# RTS591x register map
Vendor: Realtek Semiconductor Corp.; Series: RTS591x Series; File version: 1.0
CPU: ARMV8MML r0p0, little endian, MPU, FPU, VTOR, 3 interrupt priority bits, 4 SAU regions
Registers are 32-bit, read-write, reset 0x0 unless marked. A register's access mark holds for its fields unless they carry their own. Offsets are from the block's base; [hi:lo] are bit positions; {n}, {i} and the like mark numbered series.

## UART — UART Controller
Base 0x40010100
0x00 RBR ro — RECEIVE BUFFER REGISTER
  [7:0] DATA — Receive Buffer
0x00 THR (alternate view of RBR) — TRANSMIT HOLDING REGISTER
  [7:0] DATA — Transmit Holding
0x00 DLL (alternate view of RBR) — DIVISOR LATCH LOW REGISTER
  [7:0] DIVL — Divisor Latch Low Byte
0x04 DLH — DIVISOR LATCH HIGH REGISTER
  [7:0] DIVH — Divisor Latch High Byte
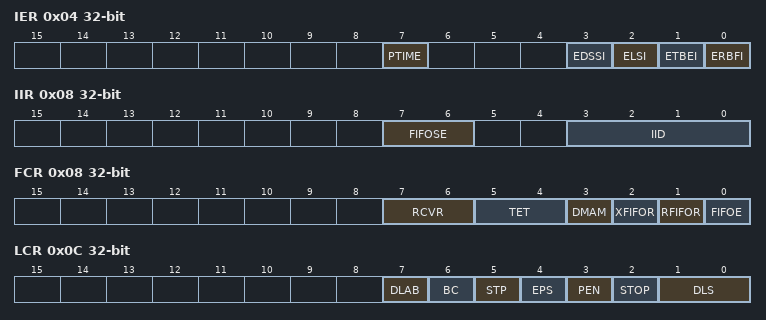
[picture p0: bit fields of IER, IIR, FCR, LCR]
0x04 IER (alternate view of DLH) — INTRRRUPT ENABLE REGISTER
  [7] PTIME — Programmable THRE Interrupt Mode Enable
    0=DISABLE (Disable programmable THRE interrupt mode); 1=ENABLE (Enable programmable THRE interrupt mode)
  [3] EDSSI — Enable Modem Status Interrupt
    0=DISABLE (Disable receiver line status interrupt); 1=ENABLE (Enable modem status interrupt)
  [2] ELSI — Enable Receiver Line Status Interrupt
    0=DISABLE (Disable receiver line status interrupt); 1=ENABLE (Enable receiver line status interrupt)
  [1] ETBEI — Enable Transmit Holding Register Empty Interrupt
    0=DISABLE (Disable transmit holding register empty interrupt); 1=ENABLE (Enable transmit holding register empty interrupt)
  [0] ERBFI — Enable Received Data Available Interrupt
    0=DISABLE (Disable received data available interrupt); 1=ENABLE (Enable received data available interrupt)
0x08 IIR ro — INTERRUPT IDENTIFICATION
  [7:6] FIFOSE — FIFOs Enabled
    0=DISABLE (FIFOs is disabled); 3=ENABLE (FIFOs is enabled); other=NOT_USED (Reserved values. Do not use.)
  [3:0] IID — Interrupt ID
    0=MODEM (Modem status); 1=HAVE_NO_INT (No interrupt pending); 2=THR_EMPTY; 4=RX_AVL (Received data available); 6=LINE_AVL (Receiver line status); 7=BUSY_DET (Busy detect); 12=CHAR_TO (Character Timeout); other=NOT_USED (Reserved values. Do not use.)
0x08 FCR (alternate view of IIR) — FIFO CONTROL REGISTER
  [7:6] RCVR — RCVR Trigger
  [5:4] TET — TX Empty Trigger
  [3] DMAM — DMA Mode
  [2] XFIFOR — XMIT FIFO Reset
  [1] RFIFOR — RCVR FIFO Reset
  [0] FIFOE — FIFO Enabled
0x0C LCR — LINE CONTROL REGISTER
  [7] DLAB — Divisor Latch Access Bit
    0=DISABLE (Disable divisor latch access); 1=ENABLE (Enable divisor latch access)
  [6] BC — Break Control Bit
    0=DISABLE (Disable break control); 1=ENABLE (Enable break control)
  [5] STP — Stick Parity
    0=DISABLE (Disable stick parity); 1=ENABLE (Enable stick parity)
  [4] EPS — Even Parity Select
    0=ODD (Odd parity); 1=EVEN (Even parity)
  [3] PEN — Parity Enable
    0=DISABLE (Disable parity); 1=ENABLE (Enable parity)
  [2] STOP — Number of Stop Bits
    0=1_BIT (1 stop bit); 1=1_5_BIT (1.5 stop bits when DLS (LCR[1:0]) is 0, else 2 stop bit)
  [1:0] DLS — Data Length Select
    {v}={v+5}_BIT (Data Length is {v+5}-bit) (v=0..3)
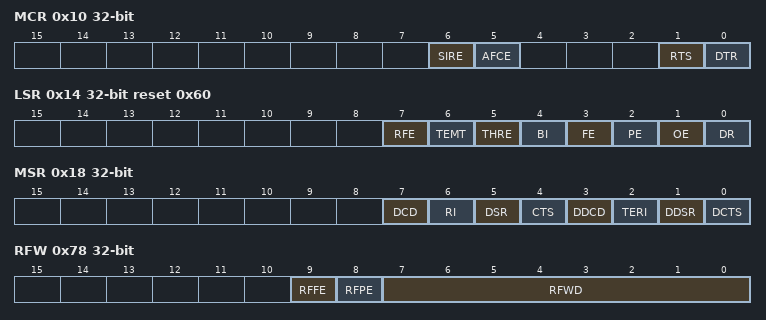
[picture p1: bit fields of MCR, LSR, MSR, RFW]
0x10 MCR — MODEM CONTROL REGISTER
  [6] SIRE — IrDA SIR Mode Enable
    0=DISABLE (Disable IrDA SIR mode); 1=ENABLE (Enable IrDA SIR mode)
  [5] AFCE — Auto Flow Control Enable
    0=DISABLE (Disable auto flow control); 1=ENABLE (Enable auto flow control)
  [1] RTS — Request to Send
    0=DEASSERT (Deassert RTS); 1=ASSERT (Assert RTS)
  [0] DTR — Data Terminal Ready
    0=DEASSERT (Deassert DTR); 1=ASSERT (Assert DTR)
0x14 LSR ro reset 0x60 — LINE STATUS REGISTER
  [7] RFE — Receiver FIFO Error
    0=NOT_OCCURRED (No receiver FIFO error); 1=OCCURRED (Receiver FIFO error occrred)
  [6] TEMT — Transmitter Empty Bit
    0=NOT_EMPTY (No transmitter empty); 1=EMPTY (Transmitter empty)
  [5] THRE — Transmit Holding Register Empty bit
    0=NOT_EMPTY (Transmit Holding Register is not empty); 1=EMPTY (Transmit Holding Register is empty)
  [4] BI — Break Interrupt bit
    0=NOT_OCCURRED (No break interrupt); 1=OCCURED (Break interrupt occrred)
  [3] FE — Framing Error bit
    0=NOT_OCCURRED (No framing error); 1=OCCURED (framing error occrred)
  [2] PE — Parity Error bit
    0=NOT_OCCURRED (No parity error); 1=OCCURED (Parity error)
  [1] OE — Overrun Error bit
    0=NOT_OCCURRED (No oerrun error); 1=OCCURED (Overrun error)
  [0] DR — Data Ready Bit
    0=NOT_READY (No data ready); 1=READY (Data ready)
0x18 MSR ro — MODEM STATUS REGISTER
  [7] DCD — Data Carrier Detect
    0=DEASSERTED (DCD input is de-asserted); 1=ASSERTED (DCD input is asserted)
  [6] RI — Ring Indicator
    0=DEASSERTED (RI input is de-asserted); 1=ASSERTED (RI input is asserted)
  [5] DSR — Data Set Ready
    0=DEASSERTED (DSR input is de-asserted); 1=ASSERTED (DSR input is asserted)
  [4] CTS — Clear to Send
    0=DEASSERTED (CTS input is de-asserted); 1=ASSERTED (CTS input is asserted)
  [3] DDCD — Delta Data Carrier Detect
    0=NO_CHANGE (No change on DCD since last read of MSR); 1=CHANGE (Change on DCD since last read of MSR)
  [2] TERI — Trailing Edge of Ring Indicator
    0=NO_CHANGE (No change on RI since last read of MSR); 1=CHANGE (Change on RI since last read of MSR)
  [1] DDSR — Delta Data Set Ready
    0=NO_CHANGE (No change on DSR since last read of MSR); 1=CHANGE (Change on DSR since last read of MSR)
  [0] DCTS — Delta Clear to Send
    0=NO_CHANGE (No change on CTS since last read of MSR); 1=CHANGE (Change on CTS since last read of MSR)
0x20 LPDLL — LOW POWER DIVISOR LATCH LOW REGISTER
0x24 LPDLH — LOW POWER DIVISOR LATCH HIGH REGISTER
{0x30+4i} SRBR[{i}] (i=0..15) — SHADOW RECEIVE BUFFER
  [7:0] DATA — Shadow Receive Buffer
{0x30+4i} STHR[{i}] (i=0..15) (alternate view of SRBR[{i}]) — SHADOW TRANSMIT HOLDING REGISTER
  [7:0] DATA — Shadow Transmit Holding Data
0x70 FAR — UART FIFO ACCESS REGISTER
  [0] FAREN — Enable FIFO Access Mode
    0=DISABLE (FIFO access mode disabled); 1=ENABLE (FIFO access mode enabled)
0x74 TFR ro — UART TRANSMIT FIFO READ
  [7:0] DATA — Top Data of Transmit FIFO Data
0x78 RFW wo — UART RECEIVE FIFO WRITE
  [9] RFFE — Receive FIFO Framing Error
  [8] RFPE — Receive FIFO Parity Error
  [7:0] RFWD — Receive FIFO Write Data
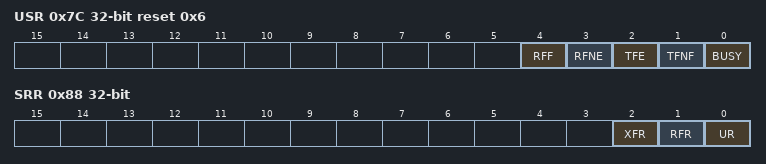
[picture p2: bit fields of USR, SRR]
0x7C USR ro reset 0x6 — UART Status Register
  [4] RFF — Receive FIFO Full
    0=NOT_FULL (Receive FIFO not full); 1=FULL (Receive FIFO Full)
  [3] RFNE — Receive FIFO Not Empty
    0=EMPTY (Receive FIFO is empty); 1=NOT_EMPTY (Receive FIFO is not empty)
  [2] TFE — Transmit FIFO Empty
    0=NOT_EMPTY (Transmit FIFO is not empty); 1=EMPTY (Transmit FIFO is empty)
  [1] TFNF — Transmit FIFO Not Full
    0=FULL (Transmit FIFO is full); 1=NOT_FULL (Transmit FIFO is not full)
  [0] BUSY — UART Busy
    0=IDLE (UART idle or inactive); 1=BUSY (UART is busy)
0x80 TFL ro — UART TRANSMIT FIFO LEVEL
0x84 RFL ro — UART RECEIVE FIFO LEVEL
0x88 SRR wo — UART SOFTWARE RESET REGISTER
  [2] XFR — XMIT FIFO Reset
  [1] RFR — RCVR FIFO Reset
  [0] UR — UART Reset
0x8C SRTS — UART SHADOW REQUEST TO SEND
  [0] SRTS — Shadow Request To Send
0x90 SBCR — UART SHADOW BREAK CONTROL REGISTER
  [0] SBCR — Shadow Break Control Bit
    0=NOTHING; 1=BREAK (Serial output is forced to the spacing (logic 0) state.)
0x94 SDMAM — UART SHADOW DMA MODE
  [0] SDMAM — Shadow Break Control Bit
    0=DO_NOTHING; 1=BREAK (Serial output is forced to the spacing (logic 0) state)
0x98 SFE — UART SHADOW FIFO ENABLE
  [0] SFE — Shadow FIFO Enable
    0=DISABLE (Disable shadow FIFO); 1=Enable shadow FIFO
0x9C SRT — UART Shadow RCVR Trigger
  [1:0] SRT — Shadow Register For RCVR Trigger Bits
    0=ONE_CHAR (One character in the FIFO); 1=ONE_QUARTER (FIFO one-fourth full); 2=ONE_HALF (FIFO one-half full); 3=TWO_LESS_FULL (FIFO 2 less than full)
0xA0 STET — UART SHADOW TX EMPTY TRIGGER
  [1:0] SRT — shadow register for the RCVR trigger bits
    0=EMPTY; 1=TWO_CHAR (2 character in the FIFO); 2=ONE_QUARTER (FIFO one-fourth full); 3=ONE_HALF (FIFO one-half full)
0xA4 HTX — UART HALT TX
  [0] HALTTX
    0=DISABLE (Halt TX disabled); 1=ENABLE (Halt TX enabled)
0xA8 DMASA wo — UART DMA SOFTWARE ACKNOWLEDGE
  [0] ACK — Software Acknowledge
